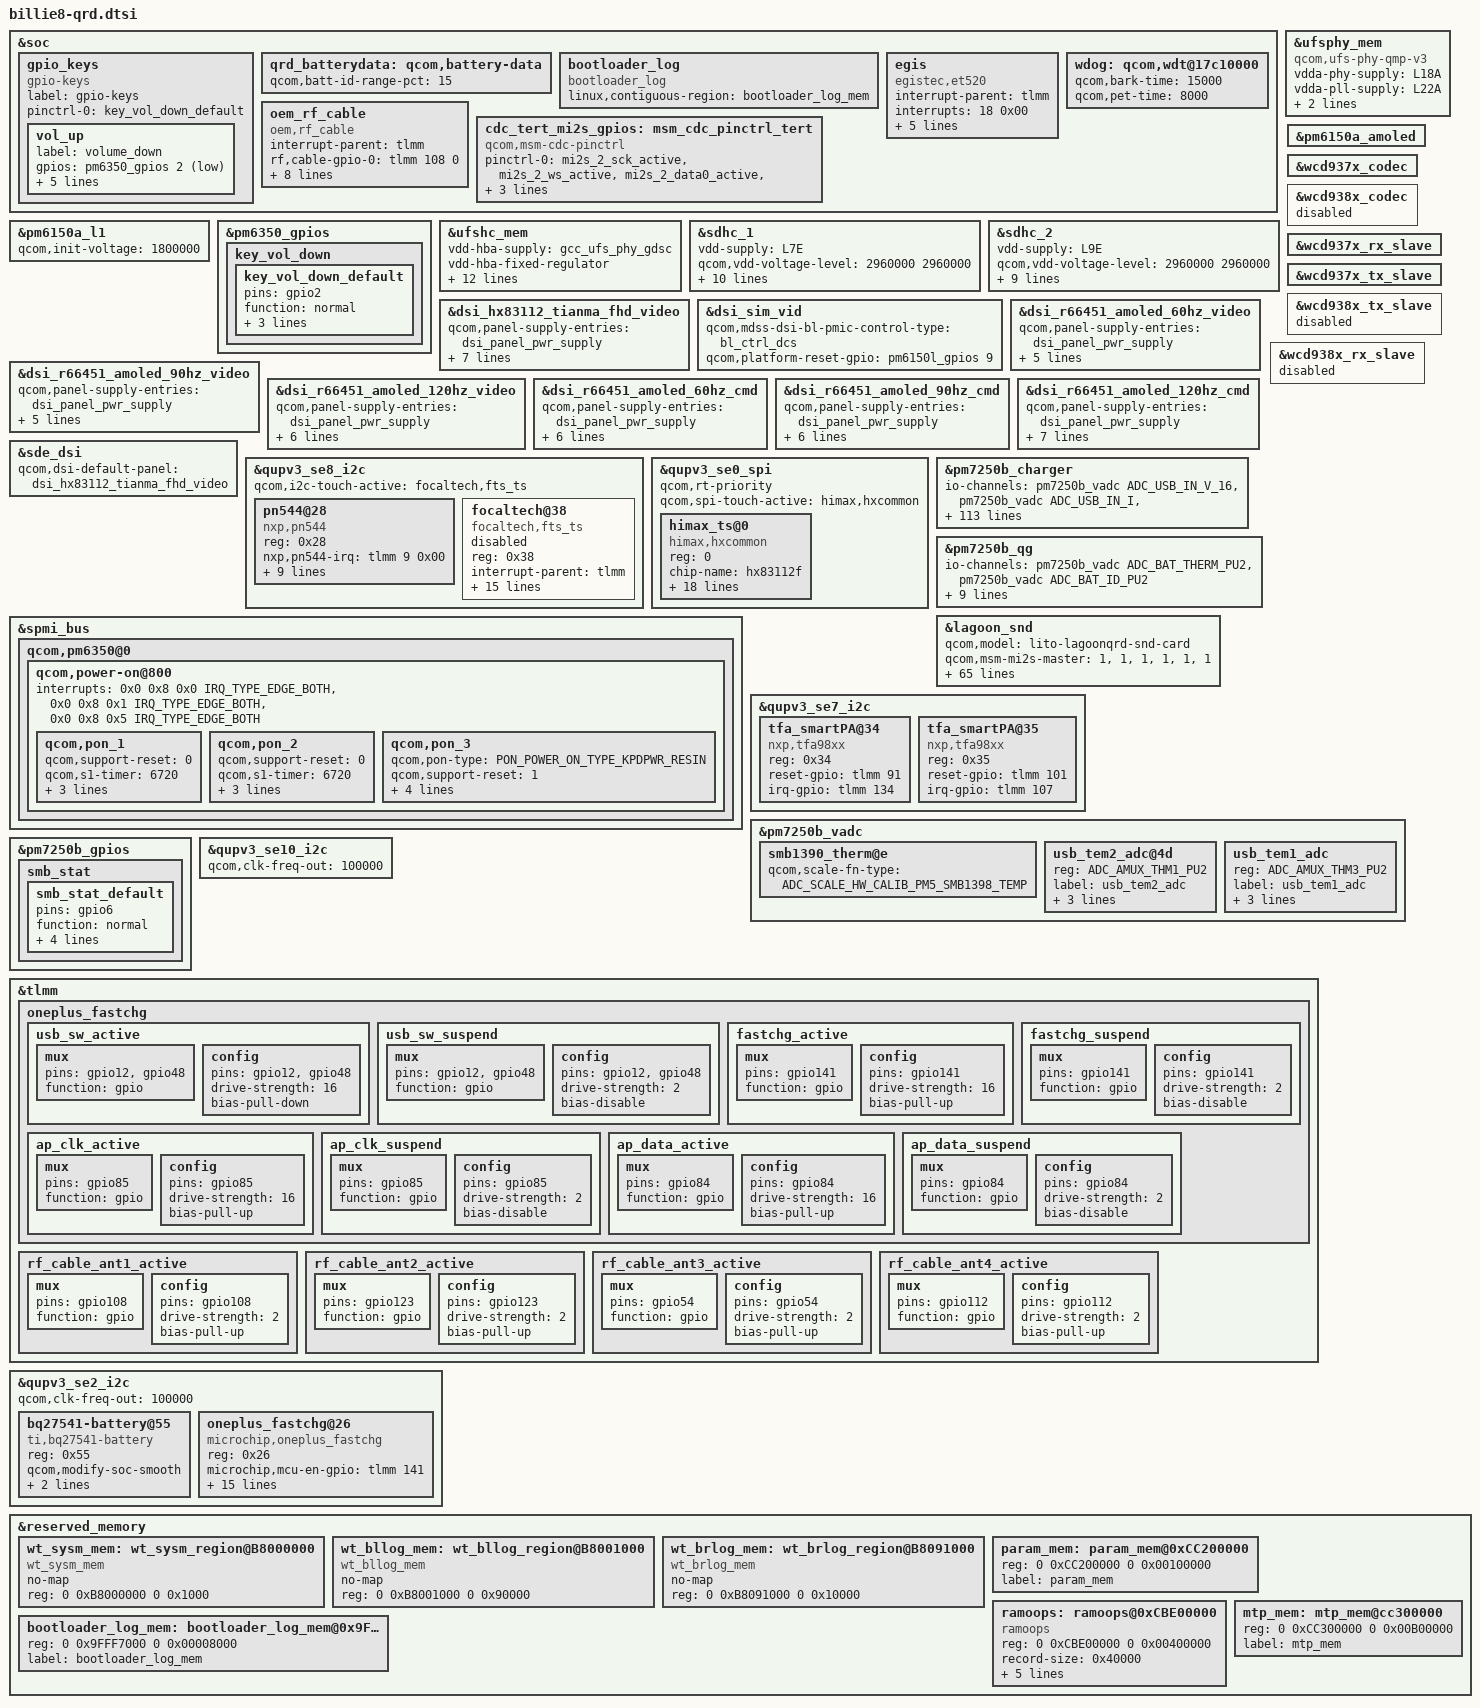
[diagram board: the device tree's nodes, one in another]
#include <dt-bindings/gpio/gpio.h>
#include <dt-bindings/input/linux-event-codes.h>
#include <dt-bindings/iio/qcom,spmi-vadc.h>
#include "lagoon-thermal-overlay.dtsi"
#include "lagoon-audio-overlay.dtsi"
#include "lagoon-sde-display.dtsi"
#include "camera/lagoon-camera-sensor-mtp.dtsi"
#include <dt-bindings/pinctrl/qcom,pmic-gpio.h>
#include <dt-bindings/iio/qcom,spmi-vadc.h>
/* @bsp, 2020/06/17 pmic S2 reset start */
#include <dt-bindings/input/qcom,qpnp-power-on.h>

&soc {
	gpio_keys {
		compatible = "gpio-keys";
		label = "gpio-keys";

		pinctrl-names = "default";
/* @bsp, Battery & Charging porting start*/
		//pinctrl-0 = <&key_vol_up_default>;
		//vol_up {
		//	label = "volume_up";
		//	gpios = <&pm6350_gpios 2 GPIO_ACTIVE_LOW>;
		//	linux,input-type = <1>;
		//	linux,code = <KEY_VOLUMEUP>;
		//	gpio-key,wakeup;
		//	debounce-interval = <15>;
		//	linux,can-disable;
		//};

		pinctrl-0 = <&key_vol_down_default>;
		vol_up {
			label = "volume_down";
			gpios = <&pm6350_gpios 2 GPIO_ACTIVE_LOW>;
			linux,input-type = <1>;
			linux,code = <KEY_VOLUMEDOWN>;
			gpio-key,wakeup;
			debounce-interval = <15>;
			linux,can-disable;
		};
/* @bsp, Battery & Charging porting end*/
	};

	qrd_batterydata: qcom,battery-data {
		qcom,batt-id-range-pct = <15>;
		#include "qg-batterydata-atl436186020H_3780mAh.dtsi"
		#include "qg-batterydata-atl466271_3300mAh.dtsi"
	};
	bootloader_log {
		compatible = "bootloader_log";
		linux,contiguous-region = <&bootloader_log_mem>;
	};

	egis {
		status = "okay";
		compatible = "egistec,et520";

		interrupt-parent = <&tlmm>;
		interrupts = <18 0x00>;

		egistec,gpio_pwr_en = <&tlmm 102 0x00>;

		egistec,gpio_rst = <&tlmm 18 0x00>;
		egistec,gpio_irq = <&tlmm 17 0x00>;
		pinctrl-names = "et520_power_active",
					"et520_power_low";
		pinctrl-0 = <&et520_power_high>;
		pinctrl-1 = <&et520_power_low>;
	};

	wdog: qcom,wdt@17c10000 {
		qcom,bark-time = <15000>;
		qcom,pet-time = <8000>;
	};
	oem_rf_cable:oem_rf_cable {
		compatible = "oem,rf_cable";
		interrupt-parent = <&tlmm>;
		rf,cable-gpio-0 = <&tlmm 108 0>;
		rf,cable-gpio-1 = <&tlmm 123 0>;
		rf,cable-gpio-2 = <&tlmm 54 0>;
		rf,cable-gpio-3 = <&tlmm 112 0>;
		rf,cable-support-timer = <0>;
		oem,rf_uevent_feature_enable;
		pinctrl-names = "oem_rf_cable_active";
		pinctrl-0 = <&rf_cable_ant1_active &rf_cable_ant2_active &rf_cable_ant3_active &rf_cable_ant4_active>;
	};
};

&pm6150a_l1 {
	qcom,init-voltage = <1800000>;
};

&pm6350_gpios {
/* @bsp, 2020/05/28 Battery & Charging porting start */
	//key_vol_up {
	//	key_vol_up_default: key_vol_up_default {
	//		pins = "gpio2";
	//		function = "normal";
	//		input-enable;
	//		bias-pull-up;
	//		power-source = <0>;
	//	};
	//};

	key_vol_down {
		key_vol_down_default: key_vol_down_default {
			pins = "gpio2";
			function = "normal";
			input-enable;
			bias-pull-up;
			power-source = <0>;
		};
	};
/* @bsp, 2020/05/28 Battery & Charging porting end*/
};

&ufsphy_mem {
	compatible = "qcom,ufs-phy-qmp-v3";

	vdda-phy-supply = <&L18A>;
	vdda-pll-supply = <&L22A>;
	vdda-phy-max-microamp = <62900>;
	vdda-pll-max-microamp = <18300>;

	status = "ok";
};

&ufshc_mem {
	vdd-hba-supply = <&gcc_ufs_phy_gdsc>;
	vdd-hba-fixed-regulator;
	vcc-supply = <&L7E>;
	vcc-voltage-level = <2950000 2960000>;
	vccq2-supply = <&L12A>;
	vccq2-voltage-level = <1800000 1800000>;
	vcc-max-microamp = <800000>;
	vccq2-min-microamp = <0>;
	vccq2-max-microamp = <800000>;
	vccq2-pwr-collapse-sup;

	qcom,vddp-ref-clk-supply = <&L22A>;
	qcom,vddp-ref-clk-max-microamp = <100>;
	qcom,vddp-ref-clk-min-uV = <1152000>;
	qcom,vddp-ref-clk-max-uV = <1200000>;
	status = "ok";
};

&sdhc_1 {
	vdd-supply = <&L7E>;
	qcom,vdd-voltage-level = <2960000 2960000>;
	qcom,vdd-current-level = <0 570000>;

	vdd-io-supply = <&L12A>;
	qcom,vdd-io-always-on;
	qcom,vdd-io-lpm-sup;
	qcom,vdd-io-voltage-level = <1800000 1800000>;
	qcom,vdd-io-current-level = <0 325000>;

	pinctrl-names = "active", "sleep";
	pinctrl-0 = <&sdc1_clk_on &sdc1_cmd_on &sdc1_data_on
					&sdc1_rclk_on>;
	pinctrl-1 = <&sdc1_clk_off &sdc1_cmd_off &sdc1_data_off
					&sdc1_rclk_off>;

	status = "ok";
};

&sdhc_2 {
	vdd-supply = <&L9E>;
	qcom,vdd-voltage-level = <2960000 2960000>;
	qcom,vdd-current-level = <0 800000>;

	vdd-io-supply = <&L6E>;
	qcom,vdd-io-voltage-level = <1800000 2950000>;
	qcom,vdd-io-current-level = <0 22000>;

	pinctrl-names = "active", "sleep";
	pinctrl-0 = <&sdc2_clk_on  &sdc2_cmd_on &sdc2_data_on &sdc2_cd_on>;
	pinctrl-1 = <&sdc2_clk_off &sdc2_cmd_off &sdc2_data_off &sdc2_cd_off>;

	/* @BSP, 2020/05/26, SD card Bringup. */
	cd-gpios = <&tlmm 94 GPIO_ACTIVE_HIGH>;

	status = "ok";
};

&pm6150a_amoled {
	status = "ok";
};
&dsi_hx83112_tianma_fhd_video {
	qcom,panel-supply-entries = <&dsi_panel_pwr_supply>;
	qcom,mdss-dsi-bl-pmic-control-type = "bl_ctrl_wled";
	qcom,mdss-dsi-bl-min-level = <1>;
	qcom,mdss-dsi-bl-max-level = <4095>;
	qcom,mdss-brightness-max-level = <4095>;
	qcom,platform-reset-gpio = <&pm6150l_gpios 9 0>;
	qcom,platform-tp-reset-gpio = <&tlmm 21 0>;
};

&dsi_sim_vid {
	qcom,mdss-dsi-bl-pmic-control-type = "bl_ctrl_dcs";
	qcom,platform-reset-gpio = <&pm6150l_gpios 9 0>;
};

&dsi_r66451_amoled_60hz_video {
	qcom,panel-supply-entries = <&dsi_panel_pwr_supply>;
	qcom,mdss-dsi-bl-pmic-control-type = "bl_ctrl_dcs";
	qcom,mdss-dsi-bl-min-level = <1>;
	qcom,mdss-dsi-bl-max-level = <255>;
	qcom,mdss-dsi-bl-max-level = <4095>;
	qcom,platform-reset-gpio = <&pm6150l_gpios 9 0>;
};

&dsi_r66451_amoled_90hz_video {
	qcom,panel-supply-entries = <&dsi_panel_pwr_supply>;
	qcom,mdss-dsi-bl-pmic-control-type = "bl_ctrl_dcs";
	qcom,mdss-dsi-bl-min-level = <1>;
	qcom,mdss-dsi-bl-max-level = <255>;
	qcom,mdss-dsi-bl-max-level = <4095>;
	qcom,platform-reset-gpio = <&pm6150l_gpios 9 0>;
};

&dsi_r66451_amoled_120hz_video {
	qcom,panel-supply-entries = <&dsi_panel_pwr_supply>;
	qcom,mdss-dsi-bl-pmic-control-type = "bl_ctrl_dcs";
	qcom,mdss-dsi-bl-min-level = <1>;
	qcom,mdss-dsi-bl-max-level = <255>;
	qcom,mdss-dsi-bl-inverted-dbv;
	qcom,mdss-dsi-bl-max-level = <4095>;
	qcom,platform-reset-gpio = <&pm6150l_gpios 9 0>;
};

&dsi_r66451_amoled_60hz_cmd {
	qcom,panel-supply-entries = <&dsi_panel_pwr_supply>;
	qcom,mdss-dsi-bl-pmic-control-type = "bl_ctrl_dcs";
	qcom,mdss-dsi-bl-min-level = <1>;
	qcom,mdss-dsi-bl-max-level = <255>;
	qcom,mdss-dsi-bl-max-level = <4095>;
	qcom,platform-te-gpio = <&tlmm 23 0>;
	qcom,platform-reset-gpio = <&pm6150l_gpios 9 0>;
};

&dsi_r66451_amoled_90hz_cmd {
	qcom,panel-supply-entries = <&dsi_panel_pwr_supply>;
	qcom,mdss-dsi-bl-pmic-control-type = "bl_ctrl_dcs";
	qcom,mdss-dsi-bl-min-level = <1>;
	qcom,mdss-dsi-bl-max-level = <255>;
	qcom,mdss-dsi-bl-max-level = <4095>;
	qcom,platform-te-gpio = <&tlmm 23 0>;
	qcom,platform-reset-gpio = <&pm6150l_gpios 9 0>;
};

&dsi_r66451_amoled_120hz_cmd {
	qcom,panel-supply-entries = <&dsi_panel_pwr_supply>;
	qcom,mdss-dsi-bl-pmic-control-type = "bl_ctrl_dcs";
	qcom,mdss-dsi-bl-min-level = <1>;
	qcom,mdss-dsi-bl-max-level = <255>;
	qcom,mdss-dsi-bl-max-level = <4095>;
	qcom,mdss-dsi-bl-inverted-dbv;
	qcom,platform-te-gpio = <&tlmm 23 0>;
	qcom,platform-reset-gpio = <&pm6150l_gpios 9 0>;
};

&sde_dsi {
	qcom,dsi-default-panel = <&dsi_hx83112_tianma_fhd_video>;
};

&qupv3_se8_i2c {
	status = "ok";
	#address-cells = <1>;
	#size-cells = <0>;
	pn544@28 {
		compatible = "nxp,pn544";
		reg = <0x28>;
		nxp,pn544-irq = <&tlmm 9 0x00>;
		nxp,pn544-ven = <&tlmm 6 0x00>;
		nxp,pn544-fw-dwnld = <&tlmm 8 0x00>;
		nxp,pn544-clk-req = <&tlmm 7 0x00>;
		interrupt-parent = <&tlmm>;
		interrupts = <9 0>;
		interrupt-names = "nfc_irq";
		pinctrl-names = "nfc_active", "nfc_suspend";
		pinctrl-0 = <&nfc_int_active &nfc_enable_active &nfc_clk_req_active>;
		pinctrl-1 = <&nfc_int_suspend &nfc_enable_suspend &nfc_clk_req_suspend>;
	};
};

&qupv3_se0_spi{
	status = "ok";
	qcom,rt-priority;
	qcom,spi-touch-active = "himax,hxcommon";
	himax_ts@0 {
		compatible = "himax,hxcommon";
		reg = <0>;
		chip-name = "hx83112f";
		spi-max-frequency = <10000000>;
		spi-cpha;
		interrupt-parent = <&tlmm>;
		interrupts = <22 0x2008>;
		touchpanel,max-num-support = <10>;
		//vdd-supply = <&pm8994_l14>;
		//avdd-supply = <&pm8994_l22>;
		touchpanel,panel-coords = <1080 2400>;
		touchpanel,display-coords = <1080 2400>;
		touchpanel,irq-gpio          = <&tlmm 22 0x2008>;
		touchpanel,reset-gpio          = <&tlmm 21 0x00>;
		touchpanel,cs-gpio          = <&tlmm 3 0x00>;
		touchpanel,tx-rx-num = <16 36>;
		touchpanel,button-type = <4>;

		/* SW Support Feature Control */
		incell_screen;
		black_gesture_support = <1>;
		fw_edge_limit_support = <1>;
		//charger_pump_support;
		//spurious_fingerprint_support;
		//fw_update_app_support;
		//smart_gesture_support;
		//game_switch_support = <0>;
		//face_detect_support = <0>;
		//lcd_refresh_rate_switch = <0>;
		//touch_hold_support = <0>;
		charge_detect_support = <1>;
		//register-is-16bit = <0>;
		//module_id_support = <0>;
		noflash_support = <1>;
		//kernel_grip_support;
		//health_monitor_support;
		//fingerprint_underscreen_support;
		//headset_pump_support;
		//pressure_report_support;
		panel  = <&dsi_hx83112_tianma_fhd_video>;
	};
};

/* @bsp, 2020/06/17 pmic S2 reset start */
&spmi_bus {
	qcom,pm6350@0 {
		qcom,power-on@800 {
			interrupts = <0x0 0x8 0x0 IRQ_TYPE_EDGE_BOTH>,
					<0x0 0x8 0x1 IRQ_TYPE_EDGE_BOTH>,
					<0x0 0x8 0x5 IRQ_TYPE_EDGE_BOTH>;
			interrupt-names = "kpdpwr", "resin", "kpdpwr-resin-bark";

			qcom,pon_1 {
				qcom,support-reset = <0>;
				qcom,s1-timer = <6720>;
				qcom,s2-timer = <2000>;
				qcom,s2-type = <PON_POWER_OFF_TYPE_HARD_RESET>;
				qcom,pull-up;
			};

			qcom,pon_2 {
				qcom,support-reset = <0>;
				qcom,s1-timer = <6720>;
				qcom,s2-timer = <2000>;
				qcom,s2-type = <PON_POWER_OFF_TYPE_HARD_RESET>;
				qcom,pull-up;
			};
			qcom,pon_3 {
				qcom,pon-type = <PON_POWER_ON_TYPE_KPDPWR_RESIN>;
				qcom,support-reset = <1>;
				qcom,s1-timer = <6720>;
				qcom,s2-timer = <2000>;
				/* @BSP Modify for shutdown */
				qcom,s2-type = <PON_POWER_OFF_TYPE_SHUTDOWN>;
				qcom,pull-up;
			};
		};
	};
};
/* @bsp, 2020/06/17 pmic S2 reset end */

&pm7250b_charger {
	status = "ok";
	io-channels = <&pm7250b_vadc ADC_USB_IN_V_16>,
		      <&pm7250b_vadc ADC_USB_IN_I>,
		      <&pm7250b_vadc ADC_CHG_TEMP>,
		      <&pm7250b_vadc ADC_DIE_TEMP>,
		      <&pm7250b_vadc ADC_AMUX_THM3_PU2>,
		      <&pm7250b_vadc ADC_SBUx>,
		      <&pm7250b_vadc ADC_VPH_PWR>,
		      <&pm7250b_vadc ADC_AMUX_THM1_PU2>;
	io-channel-names = "usb_in_voltage",
			   "usb_in_current",
			   "chg_temp",
			   "die_temp",
			   "conn_temp",
			   "sbux_res",
			   "vph_voltage",
			   "skin_temp";
	qcom,battery-data = <&qrd_batterydata>;
	qcom,sec-charger-config = <1>;
	qcom,auto-recharge-soc = <98>;
	qcom,step-charging-enable;
	qcom,sw-jeita-enable;
	qcom,charger-temp-max = <800>;
	qcom,smb-temp-max = <800>;
	qcom,suspend-input-on-debug-batt;
	qcom,fcc-stepping-enable;
	qcom,fcc-step-delay-ms = <100>;
	qcom,fcc-step-size-ua = <100000>;
	qcom,smb-internal-pull-kohm = <0>;
	qcom,en-skin-therm-mitigation;
	qcom,thermal-mitigation = <8000000 7500000 7000000 6500000 6000000
				5500000 4500000 4000000 3500000 3000000 2500000
				2000000 1500000 1000000 500000>;
};

/* @bsp, 2020/05/27 Battery & Charging porting */
&pm7250b_charger {
	qcom,dc-icl-ua = <1200000>;
	qcom,fcc-max-ua = <2000000>;
	qcom,usb-icl-ua = <1800000>;
	qcom,fv-max-uv = <4365000>;
	/* ibatmax setting for different temp regions */
	ibatmax-little-cold-ma = <350>;
	ibatmax-cool-ma = <2000>;
	ibatmax-little-cool-ma = <2000>;
	ibatmax-pre-normal-ma = <2000>;
	ibatmax-normal-ma = <2000>;
	ibatmax-warm-ma = <1150>;
	ibatmax-warm-lcd-on-ma = <550>;   /* @BSP OEM */
	ibatmax-little-cool-thr-ma = <1900>;
	ibatmax-cool-thr-ma = <1150>;
	/* vbatmax setting for different temp regions */
	vbatmax-little-cold-mv = <3975>;
	vbatmax-cool-mv = <4435>;
	vbatmax-little-cool-mv = <4435>;
	vbatmax-pre-normal-mv = <4435>;
	vbatmax-normal-mv = <4435>;
	vbatmax-warm-mv = <4130>;
	little-cool-vbat-thr-mv = <4180>;
	cool-vbat-thr-mv = <4180>;
	/* vbatdet setting for different temp regions */
	vbatdet-little-cold-mv = <3675>;
	vbatdet-cool-mv = <4235>;
	vbatdet-little-cool-mv = <4335>;
	vbatdet-pre-normal-mv = <4335>;
	vbatdet-normal-mv = <4335>;
	vbatdet-warm-mv = <4030>;
	/* temp region settings */
	/* @BSP IEEE 1725, stop charging at 0C */
	cold-bat-decidegc = <0>;/*20*/
	little-cold-bat-decidegc = <5>;/*0*/
	cool-bat-decidegc = <50>;
	little-cool-bat-decidegc = <120>;
	pre-normal-bat-decidegc = <160>;
	warm-bat-decidegc = <450>;
	hot-bat-decidegc = <500>;
	qcom,otg-cl-ua = <1500000>;
	op,sw-iterm-ma = <310>;
	op,sw-check-full-enable;
	/*ffc temp region*/
	ffc-pre-normal-decidegc = <120>;
	ffc-normal-decidegc = <350>;
	ffc-warm-decidegc = <400>;
	ffc-normal-fcc-ma = <1050>;
	ffc-warm-fcc-ma = <1100>;
	ffc-normal-cutoff-ma = <950>;
	ffc-warm-cutoff-ma = <1000>;
	ffc-full-vbat-mv = <4480>;

	/* skin thermal temp adjust the dash current */
	op,skin-thermal-high-threshold-disp-off = <42>;
	op,skin-thermal-pre-high-threshold-disp-off = <38>;
	op,skin-thermal-medium-threshold-disp-off = <39>;
	op,skin-thermal-normal-threshold-disp-off = <37>;

	op,skin-thermal-high-threshold-disp-on = <40>;
	op,skin-thermal-pre-high-threshold-disp-on = <39>;
	op,skin-thermal-little-high-threshold-disp-on = <38>;
	op,skin-thermal-pre-little-high-threshold-disp-on = <37>;
	op,skin-thermal-medium-threshold-disp-on = <36>;
	op,skin-thermal-normal-threshold-disp-on = <35>;
	op,enable-dash-current-dynamic-adjust;

	/* skin thermal temp adjust the pd current */
	op,pd-skin-thermal-high-threshold = <40>;
	op,pd-skin-thermal-normal-threshold = <38>;
	op,pd-skin-thermal-medium-threshold = <39>;
	op,pd-skin-thermal-pre-high-threshold = <39>;
	op,enable-pd-current-dynamic-adjust;

	/delete-property/ qcom,sw-jeita-enable;

	/*otg low battery current limit*/
	op,otg-icl-ctrl-enable;
	otg-low-battery-thr = <15>;
	otg-low-bat-icl-thr = <1000000>;
	otg-normal-bat-icl-thr = <1500000>;

	/* for usb connecter temperature check */
	op,normal-check-interval-period = <300>;
	op,fast-check-interval-period = <50>;
	op,fast-check-threshold-temp = <33>;
	op,high-temp-short-check-timeout = <1500>;
	op,first-protect-connecter-temp = <60>;
	op,second-protect-connecter-temp = <45>;
	op,second-protect-interval-temp = <14>;
	op,third-protect-rise-rate = <3>;
	op,third-protect-loop-temp = <40>;
	op,third-protect-interval-temp = <8>;
	op,third-protect-base-temp = <20>;

	/* for charge current&voltage curve optimize */
	op,fv-offset-voltage-mv = <50>;

	/* for 4p45v not charge full issue add sw full count numb */
	op,full-count-sw-numb = <2>;

	/* other settings */
	/*disable lpd*/
	qcom,lpd-disable;
	qcom,cutoff-voltage-with-charger = <3250>;
	qcom,msm-bus,name = "dash_clk_vote";
	qcom,msm-bus,num-cases = <2>;
	qcom,msm-bus,num-paths = <1>;
	qcom,msm-bus,vectors-KBps = <1 731 0 300000000>,
					<1 731 0 0>;

	/*usb connector hw auto detection*/
	op,usb-check = <&tlmm 93 0x00>;

	/* for external ship mode suppot */
	/* @bsp using pm7250B ship_mode */
	/*op,stm-ctrl-gpio = <&pm7250b_gpios 4 0x00>;
	pinctrl-names = "op_ship_mode_default",
			"op_usb_temp_adc_default",
			"op_usb_temp_adc_sec";*/

	/*pinctrl-0 = <&ship_mode_default>;
	pinctrl-1 = <&usb_tem1_adc_gpio_default>;
	pinctrl-2 = <&usb_tem2_adc_gpio_default>;*/

	io-channels = <&pm7250b_vadc ADC_USB_IN_V_16>,
		      <&pm7250b_vadc ADC_USB_IN_I>,
		      <&pm7250b_vadc ADC_CHG_TEMP>,
		      <&pm7250b_vadc ADC_DIE_TEMP>,
		      <&pm7250b_vadc ADC_AMUX_THM3_PU2>,
		      <&pm7250b_vadc ADC_SBUx>,
		      <&pm7250b_vadc ADC_VPH_PWR>,
		      <&pm7250b_vadc ADC_AMUX_THM1_PU2>,
		      <&pm6150l_vadc ADC_GPIO4_PU2>,
		      <&pm7250b_vadc ADC_AMUX_THM3_PU2>,
		      <&pm7250b_vadc ADC_AMUX_THM1_PU2>;

	io-channel-names = "usb_in_voltage",
			   "usb_in_current",
			   "chg_temp",
			   "die_temp",
			   "conn_temp",
			   "sbux_res",
			   "vph_voltage",
			   "skin_temp",
			   "quiet_therm",
			   "usb_tem1_adc",
			   "usb_tem2_adc";

	/* VBUS control config */
	op,vbus-ctrl-gpio = <&pm7250b_gpios 5 GPIO_ACTIVE_LOW>;
};
/* @bsp, 2020/05/27 Battery & Charging porting */

&pm7250b_qg {
	status = "ok";
	io-channels = <&pm7250b_vadc ADC_BAT_THERM_PU2>,
		      <&pm7250b_vadc ADC_BAT_ID_PU2>;
	io-channel-names = "batt-therm",
			   "batt-id";
	qcom,qg-iterm-ma = <150>;
	qcom,hold-soc-while-full;
	qcom,linearize-soc;
	qcom,cl-feedback-on;
	qcom,tcss-enable;
	qcom,fvss-enable;
	qcom,fvss-vbatt-mv = <3300>;
	qcom,bass-enable;
	qcom,use-cp-iin-sns;
};

&wcd937x_codec {
	status = "ok";
};

&wcd938x_codec {
	status = "disabled";
};

&wcd937x_rx_slave {
	status = "ok";
};

&wcd937x_tx_slave {
	status = "ok";
};

&wcd938x_tx_slave {
	status = "disabled";
};

&wcd938x_rx_slave {
	status = "disabled";
};

&lagoon_snd {
	qcom,model = "lito-lagoonqrd-snd-card";
	qcom,msm-mi2s-master = <1>, <1>, <1>, <1>, <1>, <1>;
	qcom,wcn-btfm = <1>;
	qcom,ext-disp-audio-rx = <0>;
	qcom,va-bolero-codec = <1>;
	qcom,rxtx-bolero-codec = <1>;
	qcom,audio-routing =
		"AMIC1", "MIC BIAS1",
		"MIC BIAS1", "Analog Mic1",
		"AMIC2", "MIC BIAS2",
		"MIC BIAS2", "Analog Mic2",
		"AMIC3", "MIC BIAS3",
		"MIC BIAS3", "Analog Mic3",
		"AMIC4", "MIC BIAS1",
		"MIC BIAS1", "Analog Mic4",
		"TX DMIC0", "MIC BIAS3",
		"MIC BIAS3", "Digital Mic0",
		"TX DMIC1", "MIC BIAS3",
		"MIC BIAS3", "Digital Mic1",
		"TX DMIC2", "MIC BIAS1",
		"MIC BIAS1", "Digital Mic2",
		"TX DMIC3", "MIC BIAS1",
		"MIC BIAS1", "Digital Mic3",
		"TX DMIC4", "MIC BIAS4",
		"MIC BIAS4", "Digital Mic4",
		"TX DMIC5", "MIC BIAS4",
		"MIC BIAS4", "Digital Mic5",
		"IN1_HPHL", "HPHL_OUT",
		"IN2_HPHR", "HPHR_OUT",
		"IN3_AUX", "AUX_OUT",
		"TX SWR_ADC0", "ADC1_OUTPUT",
		"TX SWR_ADC2", "ADC2_OUTPUT",
		"TX SWR_ADC3", "ADC3_OUTPUT",
		"TX SWR_DMIC0", "DMIC1_OUTPUT",
		"TX SWR_DMIC1", "DMIC2_OUTPUT",
		"TX SWR_DMIC2", "DMIC3_OUTPUT",
		"TX SWR_DMIC3", "DMIC4_OUTPUT",
		"TX SWR_DMIC4", "DMIC5_OUTPUT",
		"TX SWR_DMIC5", "DMIC6_OUTPUT",
		"TX SWR_DMIC6", "DMIC7_OUTPUT",
		"TX SWR_DMIC7", "DMIC8_OUTPUT",
		"RX_TX DEC0_INP", "TX DEC0 MUX",
		"RX_TX DEC1_INP", "TX DEC1 MUX",
		"RX_TX DEC2_INP", "TX DEC2 MUX",
		"RX_TX DEC3_INP", "TX DEC3 MUX",
		"VA_AIF1 CAP", "VA_SWR_CLK",
		"VA_AIF2 CAP", "VA_SWR_CLK",
		"VA_AIF3 CAP", "VA_SWR_CLK",
		"VA MIC BIAS3", "Digital Mic0",
		"VA MIC BIAS3", "Digital Mic1",
		"VA MIC BIAS1", "Digital Mic2",
		"VA MIC BIAS1", "Digital Mic3",
		"VA MIC BIAS4", "Digital Mic4",
		"VA MIC BIAS4", "Digital Mic5",
		"VA DMIC0", "VA MIC BIAS3",
		"VA DMIC1", "VA MIC BIAS3",
		"VA DMIC2", "VA MIC BIAS1",
		"VA DMIC3", "VA MIC BIAS1",
		"VA DMIC4", "VA MIC BIAS4",
		"VA DMIC5", "VA MIC BIAS4",
		"VA SWR_ADC0", "VA_SWR_CLK",
		"VA SWR_ADC1", "VA_SWR_CLK",
		"VA SWR_ADC2", "VA_SWR_CLK",
		"VA SWR_ADC3", "VA_SWR_CLK",
		"VA SWR_MIC0", "VA_SWR_CLK",
		"VA SWR_MIC1", "VA_SWR_CLK",
		"VA SWR_MIC2", "VA_SWR_CLK",
		"VA SWR_MIC3", "VA_SWR_CLK",
		"VA SWR_MIC4", "VA_SWR_CLK",
		"VA SWR_MIC5", "VA_SWR_CLK",
		"VA SWR_MIC6", "VA_SWR_CLK",
		"VA SWR_MIC7", "VA_SWR_CLK",
		"VA SWR_ADC0", "ADC1_OUTPUT",
		"VA SWR_ADC2", "ADC2_OUTPUT",
		"VA SWR_ADC3", "ADC3_OUTPUT",
		"VA SWR_MIC0", "DMIC1_OUTPUT",
		"VA SWR_MIC1", "DMIC2_OUTPUT",
		"VA SWR_MIC2", "DMIC3_OUTPUT",
		"VA SWR_MIC3", "DMIC4_OUTPUT",
		"VA SWR_MIC4", "DMIC5_OUTPUT",
		"VA SWR_MIC5", "DMIC6_OUTPUT",
		"VA SWR_MIC6", "DMIC7_OUTPUT",
		"VA SWR_MIC7", "DMIC8_OUTPUT";
	qcom,msm-mbhc-hphl-swh = <1>;
	qcom,msm-mbhc-gnd-swh = <0>;
	qcom,tert-mi2s-gpios = <&cdc_tert_mi2s_gpios>;
	asoc-codec  = <&stub_codec>, <&bolero>;
	asoc-codec-names = "msm-stub-codec.1", "bolero_codec";
	qcom,wsa-max-devs = <0>;
	qcom,codec-max-aux-devs = <1>;
	qcom,msm-mbhc-usbc-audio-supported = <0>;
	qcom,codec-aux-devs = <&wcd937x_codec>;
	qcom,msm_audio_ssr_devs = <&audio_apr>, <&q6core>,
				<&lpi_tlmm>, <&bolero>;
};

&qupv3_se7_i2c {
	status = "ok";
	#address-cells = <1>;
	#size-cells = <0>;
	tfa_smartPA@34 {
		status = "okay";
		compatible = "nxp,tfa98xx";
		reg = <0x34>;
		reset-gpio =<&tlmm 91 0>;
		irq-gpio = <&tlmm 134 0>;
		//vdd-supply =
	};

	tfa_smartPA@35 {
		status = "okay";
		compatible = "nxp,tfa98xx";
		reg = <0x35>;
		reset-gpio =<&tlmm 101 0>;
		irq-gpio = <&tlmm 107 0>;
		//vdd-supply =
	};
};

&soc {
	cdc_tert_mi2s_gpios: msm_cdc_pinctrl_tert {
	status = "ok";
        compatible = "qcom,msm-cdc-pinctrl";
        pinctrl-names = "aud_active", "aud_sleep";
        pinctrl-0 = <&mi2s_2_sck_active &mi2s_2_ws_active
             &mi2s_2_data0_active &mi2s_2_data1_active>;
        pinctrl-1 = <&mi2s_2_sck_sleep &mi2s_2_ws_sleep
             &mi2s_2_data0_sleep &mi2s_2_data1_sleep>;
        };
};


&qupv3_se8_i2c {
	#address-cells = <1>;
	#size-cells = <0>;

	qcom,i2c-touch-active = "focaltech,fts_ts";

	focaltech@38 {
		status = "disabled";
		compatible = "focaltech,fts_ts";
		reg = <0x38>;
		interrupt-parent = <&tlmm>;
		interrupts = <22 0x2008>;
		focaltech,reset-gpio = <&tlmm 21 0x00>;
		focaltech,irq-gpio = <&tlmm 22 0x2008>;
		focaltech,max-touch-number = <5>;
		focaltech,display-coords = <0 0 1080 2340>;

		vdd-supply = <&L6A>;

		pinctrl-names = "pmx_ts_active", "pmx_ts_suspend","pmx_ts_release";
		pinctrl-0 = <&ts_active>;
		pinctrl-1 = <&ts_int_suspend &ts_reset_suspend>;
		pinctrl-2 = <&pmx_ts_release>;

		panel = <&dsi_r66451_amoled_60hz_cmd
			 &dsi_r66451_amoled_90hz_cmd
			 &dsi_r66451_amoled_120hz_cmd
			 &dsi_r66451_amoled_60hz_video
			 &dsi_r66451_amoled_90hz_video
			 &dsi_r66451_amoled_120hz_video>;
	};
};

&pm7250b_vadc {
	smb1390_therm@e {
		qcom,scale-fn-type = <ADC_SCALE_HW_CALIB_PM5_SMB1398_TEMP>;
	};
/* @bsp 2020/06/02 add vbus/cap_ctl start */
	usb_tem2_adc@4d {
		reg = <ADC_AMUX_THM1_PU2>;
		label = "usb_tem2_adc";
		qcom,ratiometric;
		qcom,hw-settle-time = <200>;
		qcom,pre-scaling = <1 1>;
	};

	usb_tem1_adc {
		reg = <ADC_AMUX_THM3_PU2>;
		label = "usb_tem1_adc";
		qcom,ratiometric;
		qcom,hw-settle-time = <200>;
		qcom,pre-scaling = <1 1>;
	};
/* @bsp 2020/06/02 add vbus/cap_ctl end */
};

&pm7250b_gpios {
	smb_stat {
		smb_stat_default: smb_stat_default {
			pins = "gpio6";
			function = "normal";
			input-enable;
			bias-pull-up;
			qcom,pull-up-strength = <PMIC_GPIO_PULL_UP_30>;
			power-source = <0>;
		};
	};
};

&qupv3_se10_i2c {
	qcom,clk-freq-out = <100000>;
	status = "ok";
	#include "smb1398.dtsi"
};

//&smb1396 {
//	interrupts = <0x2 0xc5 0x0 IRQ_TYPE_LEVEL_LOW>;
//	interrupt-parent = <&spmi_bus>;
//	interrupt-names = "smb1396";
//	pinctrl-names = "default";
//	pinctrl-0 = <&smb_stat_default>;
//	status = "ok";
//};

//&smb1396_div2_cp_master {
//	io-channels = <&pm7250b_vadc ADC_AMUX_THM2>;
//	qcom,parallel-input-mode = <1>; /* USBIN */
//	qcom,parallel-output-mode = <2>; /* VBAT */
//	qcom,min-ilim-ua = <750000>;
//	status = "ok";
//};

//&smb1396_slave {
//	status = "ok";
//};

//&smb1396_div2_cp_slave {
//	status = "ok";
//};

/* @bsp, 2020/05/27 Battery & Charging porting */
&tlmm {
	oneplus_fastchg {
		usb_sw_active: usb_sw_active {
			mux {
				pins = "gpio12", "gpio48";
				function = "gpio";
			};

			config {
				pins = "gpio12", "gpio48";
				drive-strength = <16>;
				bias-pull-down;
			};
		};

		usb_sw_suspend: usb_sw_suspend {
			mux {
				pins = "gpio12", "gpio48";
				function = "gpio";
			};

			config {
				pins = "gpio12", "gpio48";
				drive-strength = <2>;
				bias-disable;
			};
		};

		fastchg_active: fastchg_active {
			mux {
				pins = "gpio141";
				function = "gpio";
			};

			config {
				pins = "gpio141";
				drive-strength = <16>;
				bias-pull-up;
			};
		};

		fastchg_suspend: fastchg_suspend {
			mux {
				pins = "gpio141";
				function = "gpio";
			};

			config {
				pins = "gpio141";
				drive-strength = <2>;
				bias-disable;
			};
		};

		ap_clk_active: ap_clk_active {
			mux {
				pins = "gpio85";
				function = "gpio";
			};

			config {
				pins = "gpio85";
				drive-strength = <16>;
				bias-pull-up;
			};
		};

		ap_clk_suspend: ap_clk_suspend {
			mux {
				pins = "gpio85";
				function = "gpio";
			};

			config {
				pins = "gpio85";
				drive-strength = <2>;
				bias-disable;
			};
		};

		ap_data_active: ap_data_active {
			mux {
				pins = "gpio84";
				function = "gpio";
			};

			config {
				pins = "gpio84";
				drive-strength = <16>;
				bias-pull-up;
			};
		};

		ap_data_suspend: ap_data_suspend {
			mux {
				pins = "gpio84";
				function = "gpio";
			};

			config {
				pins = "gpio84";
				drive-strength = <2>;
				bias-disable;
			};
		};
	};
	rf_cable_ant1_active: rf_cable_ant1_active {
            mux {
                pins = "gpio108";
                function = "gpio";
            };
            config {
                pins = "gpio108";
                drive-strength = <2>;
                bias-pull-up;
            };
        };
        rf_cable_ant2_active: rf_cable_ant2_active {
            mux {
                pins = "gpio123";
                function = "gpio";
            };
            config {
                pins = "gpio123";
                drive-strength = <2>;
                bias-pull-up;
            };
        };
        rf_cable_ant3_active: rf_cable_ant3_active {
            mux {
                pins = "gpio54";
                function = "gpio";
            };
            config {
                pins = "gpio54";
                drive-strength = <2>;
                bias-pull-up;
            };
        };
	rf_cable_ant4_active: rf_cable_ant4_active {
            mux {
                pins = "gpio112";
                function = "gpio";
            };
            config {
                pins = "gpio112";
                drive-strength = <2>;
                bias-pull-up;
            };
        };
};
/* @bsp, 2019/07/08 Battery & Charging porting END */

/*&qupv3_se10_i2c {*/
&qupv3_se2_i2c {
	status = "ok";
	qcom,clk-freq-out = <100000>;
	bq27541-battery@55 {
		status = "ok";
		compatible = "ti,bq27541-battery";
		reg = <0x55>;
		qcom,modify-soc-smooth;
		qcom,battery-full-param;//only for wite battery full param in guage dirver probe on 7250 platform
		op,bat-4p45v;
	};

	oneplus_fastchg@26{
		status = "ok";
		compatible = "microchip,oneplus_fastchg";
		reg = <0x26>;
		microchip,mcu-en-gpio = <&tlmm 141 0x00>;
		microchip,usb-sw-1-gpio = <&tlmm 12 0x00>;
		microchip,usb-sw-2-gpio = <&tlmm 48 0x00>;
		microchip,ap-clk = <&tlmm 85 0x00>;
		microchip,ap-data = <&tlmm 84 0x00>;

		pinctrl-names = "mux_fastchg_active",
		"mux_fastchg_suspend",
		"mcu_data_active",
		"mcu_data_suspend";
		pinctrl-0 = <&fastchg_active
		&usb_sw_active
		&ap_clk_active>;
		pinctrl-1 = <&usb_sw_suspend
		&fastchg_suspend
		&ap_clk_suspend>;
		pinctrl-2 =<&ap_data_active>;
		pinctrl-3 =<&ap_data_suspend>;
		op,fw-erase-count = <384>;
		op,fw-addr-low = <0x88>;
		op,fw-addr-high = <0>;
		op,4300mAh_4p45_support;
		op,mcl_verion;
	};
};
/* @bsp, 2020/05/27 Battery & Charging porting */

&reserved_memory {
	wt_sysm_mem: wt_sysm_region@B8000000 {
		compatible = "wt_sysm_mem";
		no-map;
		reg = <0 0xB8000000 0 0x1000>;
	};
	wt_bllog_mem: wt_bllog_region@B8001000 {
		compatible = "wt_bllog_mem";
		no-map;
		reg = <0 0xB8001000 0 0x90000>;
	};
	wt_brlog_mem: wt_brlog_region@B8091000 {
		compatible = "wt_brlog_mem";
		no-map;
		reg = <0 0xB8091000 0 0x10000>;
	};
	param_mem: param_mem@0xCC200000 {
		reg = <0 0xCC200000 0 0x00100000>;
		label = "param_mem";
	};

    ramoops: ramoops@0xCBE00000 {
        compatible = "ramoops";
        reg = <0 0xCBE00000 0 0x00400000>;
        record-size =  <0x40000>; //256x1024
        console-size = <0x40000>;
        ftrace-size =  <0x40000>;
        pmsg-size=         <0x200000>;
        devinfo-size=  <0x01000>;
        ecc-size=          <0x0>;
   };
 
   mtp_mem: mtp_mem@cc300000 {
        reg = <0 0xCC300000 0 0x00B00000>;
        label = "mtp_mem";
    };
	bootloader_log_mem: bootloader_log_mem@0x9FFF7000 {
		reg = <0 0x9FFF7000 0 0x00008000>;
		label = "bootloader_log_mem";
	};
};
